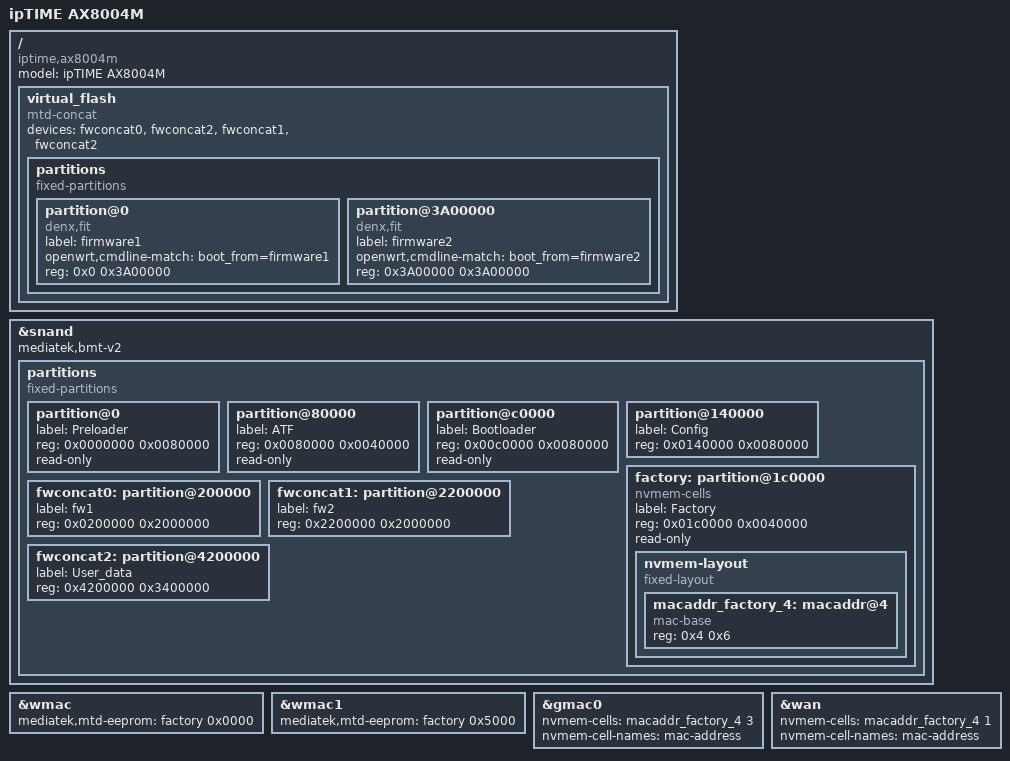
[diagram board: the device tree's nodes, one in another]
// SPDX-License-Identifier: (GPL-2.0-only OR MIT)

/dts-v1/;
#include "mt7622-iptime-ax8004m.dtsi"

/ {
	model = "ipTIME AX8004M";
	compatible = "iptime,ax8004m", "mediatek,mt7622";

	virtual_flash {
		compatible = "mtd-concat";
		devices = <&fwconcat0 &fwconcat2 &fwconcat1 &fwconcat2>;

		partitions {
			compatible = "fixed-partitions";
			#address-cells = <1>;
			#size-cells = <1>;

			partition@0 {
				label = "firmware1";
				compatible = "denx,fit";
				openwrt,cmdline-match = "boot_from=firmware1";
				reg = <0x0 0x3A00000>;
			};

			partition@3A00000 {
				label = "firmware2";
				compatible = "denx,fit";
				openwrt,cmdline-match = "boot_from=firmware2";
				reg = <0x3A00000 0x3A00000>;
			};
		};
	};
};

&snand {
	mediatek,bmt-v2;

	partitions {
		compatible = "fixed-partitions";
		#address-cells = <1>;
		#size-cells = <1>;

		partition@0 {
			label = "Preloader";
			reg = <0x0000000 0x0080000>;
			read-only;
		};

		partition@80000 {
			label = "ATF";
			reg = <0x0080000 0x0040000>;
			read-only;
		};

		partition@c0000 {
			label = "Bootloader";
			reg = <0x00c0000 0x0080000>;
			read-only;
		};

		partition@140000 {
			label = "Config";
			reg = <0x0140000 0x0080000>;
		};

		factory: partition@1c0000 {
			label = "Factory";
			reg = <0x01c0000 0x0040000>;
			read-only;
		};

		fwconcat0: partition@200000 {
			label = "fw1";
			reg = <0x0200000 0x2000000>;
		};

		fwconcat1: partition@2200000 {
			label = "fw2";
			reg = <0x2200000 0x2000000>;
		};

		fwconcat2: partition@4200000 {
			label = "User_data";
			reg = <0x4200000 0x3400000>;
		};
	};
};

&factory {
	compatible = "nvmem-cells";
	#address-cells = <1>;
	#size-cells = <1>;

	nvmem-layout {
		compatible = "fixed-layout";
		#address-cells = <1>;
		#size-cells = <1>;

		macaddr_factory_4: macaddr@4 {
			compatible = "mac-base";
			reg = <0x4 0x6>;
			#nvmem-cell-cells = <1>;
		};
	};
};

&wmac {
	mediatek,mtd-eeprom = <&factory 0x0000>;
	status = "okay";
};

&wmac1 {
	mediatek,mtd-eeprom = <&factory 0x5000>;
};

&gmac0 {
	nvmem-cells = <&macaddr_factory_4 3>;
	nvmem-cell-names = "mac-address";
};

&wan {
	nvmem-cells = <&macaddr_factory_4 1>;
	nvmem-cell-names = "mac-address";
};
